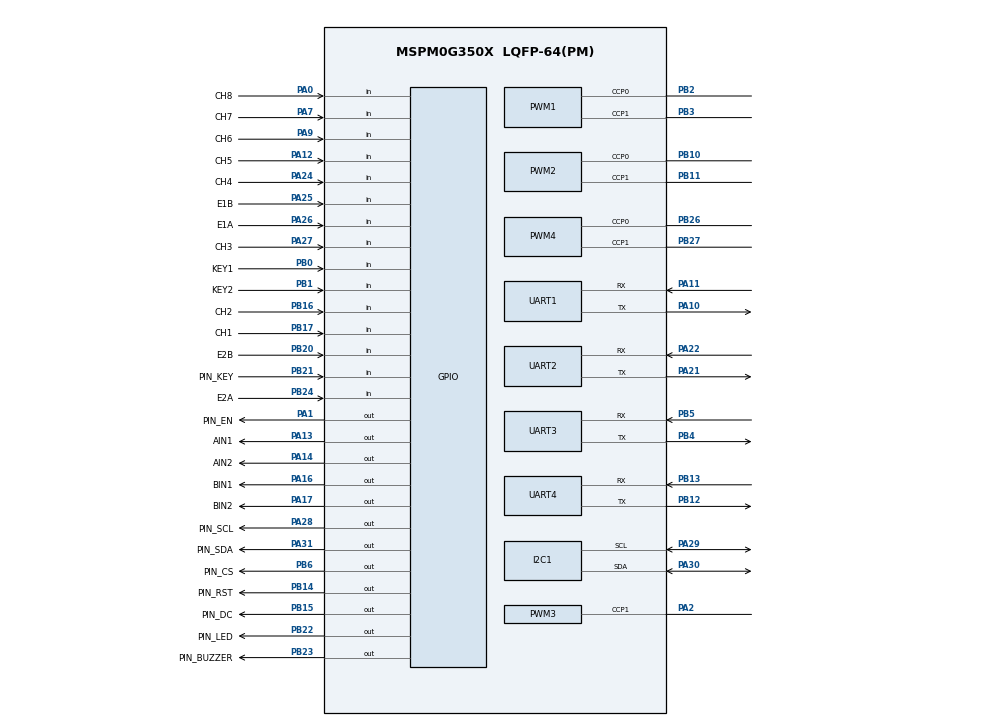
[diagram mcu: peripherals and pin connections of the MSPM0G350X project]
/**
 * Minimal TianMengXing MSPM0G3507 tracking-car base configuration.
 *
 * @cliArgs --device "MSPM0G350X" --package "LQFP-64(PM)" --part "Default" --product "mspm0_sdk@2.01.00.03"
 * @versions {"tool":"1.20.0+3587"}
 */

const ADC12   = scripting.addModule("/ti/driverlib/ADC12", {}, false);
const ADC121  = ADC12.addInstance();
const GPIO    = scripting.addModule("/ti/driverlib/GPIO", {}, false);
const GPIO1   = GPIO.addInstance();
const GPIO2   = GPIO.addInstance();
const GPIO3   = GPIO.addInstance();
const GPIO4   = GPIO.addInstance();
const GPIO5   = GPIO.addInstance();
const GPIO6   = GPIO.addInstance();
const GPIO7   = GPIO.addInstance();
const GPIO8   = GPIO.addInstance();
const GPIO9   = GPIO.addInstance();
const GPIO10  = GPIO.addInstance();
const GPIO11  = GPIO.addInstance();
const GPIO12  = GPIO.addInstance();
const GPIO13  = GPIO.addInstance();
const GPIO14  = GPIO.addInstance();
const GPIO15  = GPIO.addInstance();
const GPIO16  = GPIO.addInstance();
const I2C     = scripting.addModule("/ti/driverlib/I2C", {}, false);
const I2C1    = I2C.addInstance();
const PWM     = scripting.addModule("/ti/driverlib/PWM", {}, false);
const PWM1    = PWM.addInstance();
const PWM2    = PWM.addInstance();
const PWM3    = PWM.addInstance();
const PWM4    = PWM.addInstance();
const SYSCTL  = scripting.addModule("/ti/driverlib/SYSCTL");
const SYSTICK = scripting.addModule("/ti/driverlib/SYSTICK");
const TIMER   = scripting.addModule("/ti/driverlib/TIMER", {}, false);
const TIMER1  = TIMER.addInstance();
const UART    = scripting.addModule("/ti/driverlib/UART", {}, false);
const UART1   = UART.addInstance();
const UART2   = UART.addInstance();
const UART3   = UART.addInstance();
const UART4   = UART.addInstance();

/* 80 MHz CPU clock, matching the proven Arc_Track project. */
const divider7       = system.clockTree["PLL_PDIV"];
divider7.divideValue = 2;

const divider9       = system.clockTree["UDIV"];
divider9.divideValue = 2;

const multiplier2         = system.clockTree["PLL_QDIV"];
multiplier2.multiplyValue = 5;

const mux8       = system.clockTree["HSCLKMUX"];
mux8.inputSelect = "HSCLKMUX_SYSPLL2X";

SYSCTL.forceDefaultClkConfig = true;
SYSCTL.clockTreeEn           = true;

SYSTICK.periodEnable  = true;
SYSTICK.systickEnable = true;
SYSTICK.period        = 16777216;

/*
 * 外部电池分压输入。PA15 在天猛星板上没有自动连接电池，必须由车体底板
 * 将电池正极经分压网络接入；严禁把电池或 5 V 直接接到 PA15。
 */
ADC121.$name                             = "ADC12_VOLTAGE";
ADC121.sampClkDiv                        = "DL_ADC12_CLOCK_DIVIDE_8";
ADC121.repeatMode                        = false;
ADC121.sampleTime0                       = "0.006 ms";
ADC121.enabledInterrupts                 = ["DL_ADC12_INTERRUPT_MEM0_RESULT_LOADED"];
ADC121.interruptPriority                 = "3";
ADC121.adcPin0Config.$name               = "ti_driverlib_gpio_ADC12_VOLTAGE_C0";
ADC121.adcPin0Config.hideOutputInversion = scripting.forceWrite(false);
ADC121.peripheral.$assign                = "ADC1";
ADC121.peripheral.adcPin0.$assign        = "PA15";

/* Four-wire software OLED. */
GPIO1.$name                           = "OLED_RST";
GPIO1.associatedPins[0].$name         = "PIN_RST";
GPIO1.associatedPins[0].initialValue  = "SET";
GPIO1.associatedPins[0].pin.$assign   = "PB14";

GPIO2.$name                           = "OLED_DC";
GPIO2.associatedPins[0].$name         = "PIN_DC";
GPIO2.associatedPins[0].initialValue  = "SET";
GPIO2.associatedPins[0].pin.$assign   = "PB15";

GPIO3.$name                           = "OLED_SCL";
GPIO3.associatedPins[0].$name         = "PIN_SCL";
GPIO3.associatedPins[0].initialValue  = "SET";
GPIO3.associatedPins[0].pin.$assign   = "PA28";

GPIO4.$name                           = "OLED_SDA";
GPIO4.associatedPins[0].$name         = "PIN_SDA";
GPIO4.associatedPins[0].initialValue  = "SET";
GPIO4.associatedPins[0].pin.$assign   = "PA31";

/* TianMengXing user button: PB21, active low, internal pull-up. */
GPIO5.$name                                = "USER_KEY";
GPIO5.associatedPins[0].$name              = "PIN_KEY";
GPIO5.associatedPins[0].direction          = "INPUT";
GPIO5.associatedPins[0].internalResistor   = "PULL_UP";
GPIO5.associatedPins[0].pin.$assign        = "PB21";

/* TianMengXing on-board LED: PB22, active high. */
GPIO6.$name                           = "BOARD_LED";
GPIO6.associatedPins[0].$name         = "PIN_LED";
GPIO6.associatedPins[0].initialValue  = "CLEARED";
GPIO6.associatedPins[0].pin.$assign   = "PB22";

/* Keep the on-board W25Q128 deselected. PB7-PB9 remain unused/high impedance. */
GPIO7.$name                           = "FLASH_GUARD";
GPIO7.associatedPins[0].$name         = "PIN_CS";
GPIO7.associatedPins[0].initialValue  = "SET";
GPIO7.associatedPins[0].pin.$assign   = "PB6";

/* TB6612 direction outputs. */
GPIO8.port                          = "PORTA";
GPIO8.$name                         = "BIN";
GPIO8.associatedPins.create(2);
GPIO8.associatedPins[0].$name       = "BIN1";
GPIO8.associatedPins[0].pin.$assign = "PA16";
GPIO8.associatedPins[1].$name       = "BIN2";
GPIO8.associatedPins[1].pin.$assign = "PA17";

GPIO9.port                          = "PORTA";
GPIO9.$name                         = "AIN";
GPIO9.associatedPins.create(2);
GPIO9.associatedPins[0].$name       = "AIN1";
GPIO9.associatedPins[0].pin.$assign = "PA13";
GPIO9.associatedPins[1].$name       = "AIN2";
GPIO9.associatedPins[1].pin.$assign = "PA14";

/* Quadrature encoders, preserving the proven interrupt mapping. */
GPIO10.$name                               = "ENCODERA";
GPIO10.associatedPins.create(2);
GPIO10.associatedPins[0].$name             = "E1A";
GPIO10.associatedPins[0].direction         = "INPUT";
GPIO10.associatedPins[0].polarity          = "RISE";
GPIO10.associatedPins[0].interruptPriority = "0";
GPIO10.associatedPins[0].interruptEn       = true;
GPIO10.associatedPins[0].pin.$assign       = "PA26";
GPIO10.associatedPins[1].$name             = "E1B";
GPIO10.associatedPins[1].direction         = "INPUT";
GPIO10.associatedPins[1].polarity          = "RISE";
GPIO10.associatedPins[1].interruptPriority = "0";
GPIO10.associatedPins[1].interruptEn       = true;
GPIO10.associatedPins[1].pin.$assign       = "PA25";

GPIO11.$name                               = "ENCODERB";
GPIO11.associatedPins.create(2);
GPIO11.associatedPins[0].$name             = "E2A";
GPIO11.associatedPins[0].direction         = "INPUT";
GPIO11.associatedPins[0].polarity          = "RISE";
GPIO11.associatedPins[0].interruptPriority = "0";
GPIO11.associatedPins[0].interruptEn       = true;
GPIO11.associatedPins[0].pin.$assign       = "PB24";
GPIO11.associatedPins[1].$name             = "E2B";
GPIO11.associatedPins[1].direction         = "INPUT";
GPIO11.associatedPins[1].polarity          = "RISE";
GPIO11.associatedPins[1].interruptPriority = "0";
GPIO11.associatedPins[1].interruptEn       = true;
GPIO11.associatedPins[1].pin.$assign       = "PB20";

/* Eight digital tracking inputs. CH8 is the leftmost channel, CH1 the rightmost. */
GPIO12.port = "PORTA";
GPIO12.$name = "TRACK_A";
GPIO12.associatedPins.create(6);
GPIO12.associatedPins[0].$name = "CH8";
GPIO12.associatedPins[0].direction = "INPUT";
GPIO12.associatedPins[0].pin.$assign = "PA0";
GPIO12.associatedPins[1].$name = "CH7";
GPIO12.associatedPins[1].direction = "INPUT";
GPIO12.associatedPins[1].pin.$assign = "PA7";
GPIO12.associatedPins[2].$name = "CH6";
GPIO12.associatedPins[2].direction = "INPUT";
GPIO12.associatedPins[2].pin.$assign = "PA9";
GPIO12.associatedPins[3].$name = "CH5";
GPIO12.associatedPins[3].direction = "INPUT";
GPIO12.associatedPins[3].pin.$assign = "PA12";
GPIO12.associatedPins[4].$name = "CH4";
GPIO12.associatedPins[4].direction = "INPUT";
GPIO12.associatedPins[4].pin.$assign = "PA24";
GPIO12.associatedPins[5].$name = "CH3";
GPIO12.associatedPins[5].direction = "INPUT";
GPIO12.associatedPins[5].pin.$assign = "PA27";

GPIO13.port = "PORTB";
GPIO13.$name = "TRACK_B";
GPIO13.associatedPins.create(2);
GPIO13.associatedPins[0].$name = "CH2";
GPIO13.associatedPins[0].direction = "INPUT";
GPIO13.associatedPins[0].pin.$assign = "PB16";
GPIO13.associatedPins[1].$name = "CH1";
GPIO13.associatedPins[1].direction = "INPUT";
GPIO13.associatedPins[1].pin.$assign = "PB17";

/* Two optional expansion buttons, both active low with internal pull-ups. */
GPIO14.port = "PORTB";
GPIO14.$name = "EXT_KEYS";
GPIO14.associatedPins.create(2);
GPIO14.associatedPins[0].$name = "KEY1";
GPIO14.associatedPins[0].direction = "INPUT";
GPIO14.associatedPins[0].internalResistor = "PULL_UP";
GPIO14.associatedPins[0].pin.$assign = "PB0";
GPIO14.associatedPins[1].$name = "KEY2";
GPIO14.associatedPins[1].direction = "INPUT";
GPIO14.associatedPins[1].internalResistor = "PULL_UP";
GPIO14.associatedPins[1].pin.$assign = "PB1";

/* Active buzzer control: power-on default is off. */
GPIO15.$name = "BUZZER";
GPIO15.associatedPins[0].$name = "PIN_BUZZER";
GPIO15.associatedPins[0].initialValue = "CLEARED";
GPIO15.associatedPins[0].pin.$assign = "PB23";

/* General-purpose enable/output: power-on default is off. */
GPIO16.$name = "GENERAL_EN";
GPIO16.associatedPins[0].$name = "PIN_EN";
GPIO16.associatedPins[0].initialValue = "CLEARED";
GPIO16.associatedPins[0].pin.$assign = "PA1";

/* 10 kHz dual PWM, unchanged from the proven chassis project. */
PWM1.$name                      = "PWM_0";
PWM1.timerStartTimer            = true;
PWM1.pwmMode                    = "EDGE_ALIGN_UP";
PWM1.timerCount                 = 8000;
PWM1.peripheral.$assign         = "TIMA1";
PWM1.peripheral.ccp0Pin.$assign = "PB2";
PWM1.peripheral.ccp1Pin.$assign = "PB3";
PWM1.PWM_CHANNEL_0.$name        = "ti_driverlib_pwm_PWMTimerCC0";
PWM1.PWM_CHANNEL_1.$name        = "ti_driverlib_pwm_PWMTimerCC1";
PWM1.ccp0PinConfig.$name        = "ti_driverlib_gpio_PWM_C0";
PWM1.ccp1PinConfig.$name        = "ti_driverlib_gpio_PWM_C1";

/* Two 50 Hz servo outputs. TIMG8 BUSCLK is 40 MHz: 40 MHz / 40 / 20000. */
PWM2.$name                      = "SERVO_PWM";
PWM2.timerStartTimer            = true;
PWM2.pwmMode                    = "EDGE_ALIGN_UP";
PWM2.clockPrescale              = 40;
PWM2.timerCount                 = 20000;
PWM2.peripheral.$assign         = "TIMG8";
PWM2.peripheral.ccp0Pin.$assign = "PB10";
PWM2.peripheral.ccp1Pin.$assign = "PB11";
PWM2.PWM_CHANNEL_0.$name        = "ti_driverlib_pwm_SERVO_CC0";
PWM2.PWM_CHANNEL_1.$name        = "ti_driverlib_pwm_SERVO_CC1";
PWM2.ccp0PinConfig.$name        = "ti_driverlib_gpio_SERVO_C0";
PWM2.ccp1PinConfig.$name        = "ti_driverlib_gpio_SERVO_C1";

/* 20 kHz electromagnet/auxiliary power PWM; output starts at zero. */
PWM3.$name                      = "MAGNET_PWM";
PWM3.timerStartTimer            = true;
PWM3.pwmMode                    = "EDGE_ALIGN_UP";
PWM3.ccIndex                    = [1];
PWM3.timerCount                 = 4000;
PWM3.peripheral.$assign         = "TIMG7";
PWM3.peripheral.ccp1Pin.$assign = "PA2";
PWM3.PWM_CHANNEL_1.$name        = "ti_driverlib_pwm_MAGNET_CC1";
PWM3.ccp1PinConfig.$name        = "ti_driverlib_gpio_MAGNET_C1";

/* Generic two-channel mechanism PWM/step outputs, both default to zero. */
PWM4.$name                      = "MECHANISM_PWM";
PWM4.timerStartTimer            = true;
PWM4.pwmMode                    = "EDGE_ALIGN_UP";
PWM4.timerCount                 = 8000;
PWM4.peripheral.$assign         = "TIMG6";
PWM4.peripheral.ccp0Pin.$assign = "PB26";
PWM4.peripheral.ccp1Pin.$assign = "PB27";
PWM4.PWM_CHANNEL_0.$name        = "ti_driverlib_pwm_MECHANISM_CC0";
PWM4.PWM_CHANNEL_1.$name        = "ti_driverlib_pwm_MECHANISM_CC1";
PWM4.ccp0PinConfig.$name        = "ti_driverlib_gpio_MECHANISM_C0";
PWM4.ccp1PinConfig.$name        = "ti_driverlib_gpio_MECHANISM_C1";

/* One millisecond time base; chassis control executes every fifth tick. */
TIMER1.$name              = "SYSTEM_TICK";
TIMER1.timerClkPrescale   = 32;
TIMER1.timerMode          = "PERIODIC";
TIMER1.timerPeriod        = "1 ms";
TIMER1.timerStartTimer    = true;
TIMER1.interrupts         = ["ZERO"];
TIMER1.interruptPriority  = "2";
TIMER1.peripheral.$assign = "TIMG0";

/* On-board Type-C/CH340 diagnostics. No receive command/control path. */
UART1.$name                    = "DEBUG_UART";
UART1.targetBaudRate           = 115200;
UART1.peripheral.$assign       = "UART0";
UART1.peripheral.rxPin.$assign = "PA11";
UART1.peripheral.txPin.$assign = "PA10";
UART1.txPinConfig.$name        = "ti_driverlib_gpio_DEBUG_UART_TX";
UART1.rxPinConfig.$name        = "ti_driverlib_gpio_DEBUG_UART_RX";

/* JY901S receive port, 9600 8N1 by default. */
UART2.$name                    = "JY901S_UART";
UART2.targetBaudRate           = 9600;
UART2.enabledInterrupts        = ["RX"];
UART2.interruptPriority        = "1";
UART2.peripheral.$assign       = "UART2";
UART2.peripheral.rxPin.$assign = "PA22";
UART2.peripheral.txPin.$assign = "PA21";
UART2.txPinConfig.$name        = "ti_driverlib_gpio_JY901S_UART_TX";
UART2.rxPinConfig.$name        = "ti_driverlib_gpio_JY901S_UART_RX";

/* Optional 3.3 V DRF1609H ZigBee transparent link; no motion-control parser. */
UART3.$name                    = "ZIGBEE_UART";
UART3.targetBaudRate           = 38400;
UART3.peripheral.$assign       = "UART1";
UART3.peripheral.rxPin.$assign = "PB5";
UART3.peripheral.txPin.$assign = "PB4";
UART3.txPinConfig.$name        = "ti_driverlib_gpio_ZIGBEE_UART_TX";
UART3.rxPinConfig.$name        = "ti_driverlib_gpio_ZIGBEE_UART_RX";

/* Reserved camera/vision serial port. */
UART4.$name                    = "CAMERA_UART";
UART4.targetBaudRate           = 115200;
UART4.peripheral.$assign       = "UART3";
UART4.peripheral.rxPin.$assign = "PB13";
UART4.peripheral.txPin.$assign = "PB12";
UART4.txPinConfig.$name        = "ti_driverlib_gpio_CAMERA_UART_TX";
UART4.rxPinConfig.$name        = "ti_driverlib_gpio_CAMERA_UART_RX";

/* Reserved 400 kHz expansion I2C controller. */
I2C1.$name                   = "EXPANSION_I2C";
I2C1.basicEnableController   = true;
I2C1.basicControllerBusSpeed = 400000;
I2C1.peripheral.$assign      = "I2C1";
I2C1.peripheral.sclPin.$assign = "PA29";
I2C1.peripheral.sdaPin.$assign = "PA30";

const Board = scripting.addModule("/ti/driverlib/Board", {}, false);
Board.peripheral.$suggestSolution          = "DEBUGSS";
Board.peripheral.swclkPin.$suggestSolution = "PA20";
Board.peripheral.swdioPin.$suggestSolution = "PA19";
